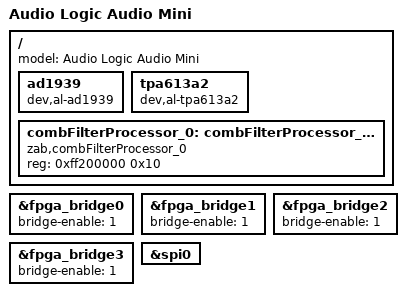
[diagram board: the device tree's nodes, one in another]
// SPDX-License-Identifier: GPL-2.0+
#include "socfpga_cyclone5_de0.dtsi"

/{
    model = "Audio Logic Audio Mini";

    ad1939 {
        compatible = "dev,al-ad1939";
    };

    tpa613a2 {
        compatible = "dev,al-tpa613a2";
    };

};




/{
    combFilterProcessor_0: combFilterProcessor_0@ff200000{
        compatible = "zab,combFilterProcessor_0";
        reg = <0xff200000 0x10>;
    };
};



&fpga_bridge0 {
  status = "okay";
  bridge-enable = <1>;
};

&fpga_bridge1 {
  status = "okay";
  bridge-enable = <1>;
};

&fpga_bridge2 {
  status = "okay";
  bridge-enable = <1>;
};

&fpga_bridge3 {
  status = "okay";
  bridge-enable = <1>;
};

&spi0{
    status = "okay";
};
